# nrf52805 register map
Vendor: Nordic Semiconductor; Series: nrf52; File version: 1
CPU: CM4 r0p1, little endian, MPU, no FPU, 3 interrupt priority bits
Registers are 32-bit, read-write, reset 0x0 unless marked. A register's access mark holds for its fields unless they carry their own. Offsets are from the block's base; [hi:lo] are bit positions; lines under a group give offsets from that group; {n}, {i} and the like mark numbered series.

## NVMC — Non Volatile Memory Controller
Base 0x4001E000
0x400 READY ro reset 0x1 — Ready flag
  [0] READY — NVMC is ready or busy
    0=Busy (NVMC is busy (on-going write or erase operation)); 1=Ready (NVMC is ready)
0x504 CONFIG — Configuration register
  [1:0] WEN — Program memory access mode. It is strongly recommended to only activate erase and write modes when they are actively used.
    0=Ren (Read only access); 1=Wen (Write enabled); 2=Een (Erase enabled)
0x508 ERASEPAGE wo — Register for erasing a page in code area
  [31:0] ERASEPAGE — Register for starting erase of a page in code area
0x508 ERASEPCR1 wo (alternate view of ERASEPAGE) — Deprecated register - Register for erasing a page in code area, equivalent to ERASEPAGE
  [31:0] ERASEPCR1 — Register for erasing a page in code area, equivalent to ERASEPAGE
0x50C ERASEALL wo — Register for erasing all non-volatile user memory
  [0] ERASEALL — Erase all non-volatile memory including UICR registers. The erase must be enabled using CONFIG.WEN before the non-volatile memory can be erased.
    0=NoOperation; 1=Erase (Start chip erase)
0x510 ERASEPCR0 wo — Deprecated register - Register for erasing a page in code area, equivalent to ERASEPAGE
  [31:0] ERASEPCR0 — Register for starting erase of a page in code area, equivalent to ERASEPAGE
0x514 ERASEUICR wo — Register for erasing user information configuration registers
  [0] ERASEUICR — Register starting erase of all user information configuration registers. The erase must be enabled using CONFIG.WEN before the UICR can be erased.
    0=NoOperation; 1=Erase (Start erase of UICR)
0x518 ERASEPAGEPARTIAL wo — Register for partial erase of a page in code area
  [31:0] ERASEPAGEPARTIAL — Register for starting partial erase of a page in code area
0x51C ERASEPAGEPARTIALCFG reset 0xA — Register for partial erase configuration
  [6:0] DURATION — Duration of the partial erase in milliseconds

## PPI — Programmable Peripheral Interconnect
Base 0x4001F000
{0x0+8i} TASKS_CHG[{i}] (i=0..5) group — Channel group tasks
  0x00 EN wo — Description cluster: Enable channel group n
    [0] EN — Enable channel group n
      1=Trigger task
  0x04 DIS wo — Description cluster: Disable channel group n
    [0] DIS — Disable channel group n
      1=Trigger task
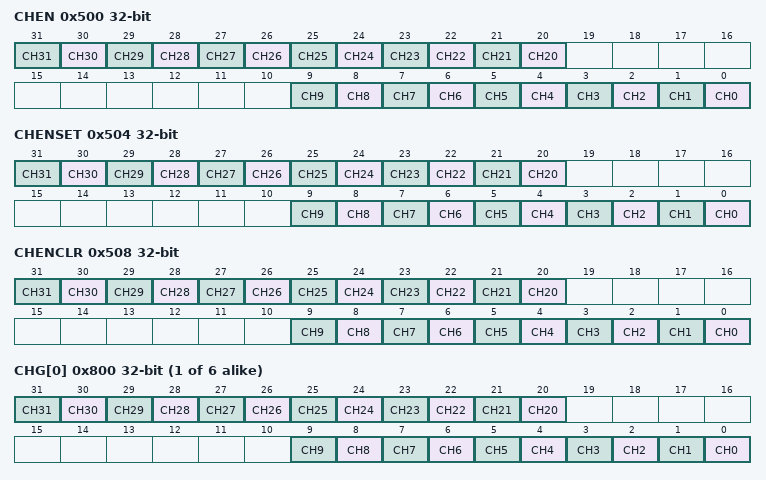
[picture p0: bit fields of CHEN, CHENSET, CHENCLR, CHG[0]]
0x500 CHEN — Channel enable register
  [all] fields
    0=Disabled (Disable channel); 1=Enabled (Enable channel)
  [n] CH{n} (n=20..31) — Enable or disable channel {n}
  [n] CH{n} (n=0..9) — Enable or disable channel {n}
0x504 CHENSET write-1-sets — Channel enable set register
  [all] fields
    on read: 0=Disabled (Read: channel disabled); 1=Enabled (Read: channel enabled) | on write: 1=Set (Write: Enable channel)
  [n] CH{n} (n=20..31) — Channel {n} enable set register. Writing '0' has no effect.
  [n] CH{n} (n=0..9) — Channel {n} enable set register. Writing '0' has no effect.
0x508 CHENCLR write-1-clears — Channel enable clear register
  [all] fields
    on read: 0=Disabled (Read: channel disabled); 1=Enabled (Read: channel enabled) | on write: 1=Clear (Write: disable channel)
  [n] CH{n} (n=20..31) — Channel {n} enable clear register. Writing '0' has no effect.
  [n] CH{n} (n=0..9) — Channel {n} enable clear register. Writing '0' has no effect.
{0x510+8i} CH[{i}] (i=0..9) group — PPI Channel
  0x00 EEP — Description cluster: Channel n event endpoint
    [31:0] EEP — Pointer to event register. Accepts only addresses to registers from the Event group.
  0x04 TEP — Description cluster: Channel n task endpoint
    [31:0] TEP — Pointer to task register. Accepts only addresses to registers from the Task group.
{0x800+4i} CHG[{i}] (i=0..5) — Description collection: Channel group n
  [all] fields
    0=Excluded; 1=Included
  [n] CH{n} (n=20..31) — Include or exclude channel {n}
  [n] CH{n} (n=0..9) — Include or exclude channel {n}
{0x910+4i} FORK[{i}] (i=0..31) group
  0x00 TEP — Description cluster: Channel n task endpoint
    [31:0] TEP — Pointer to task register
